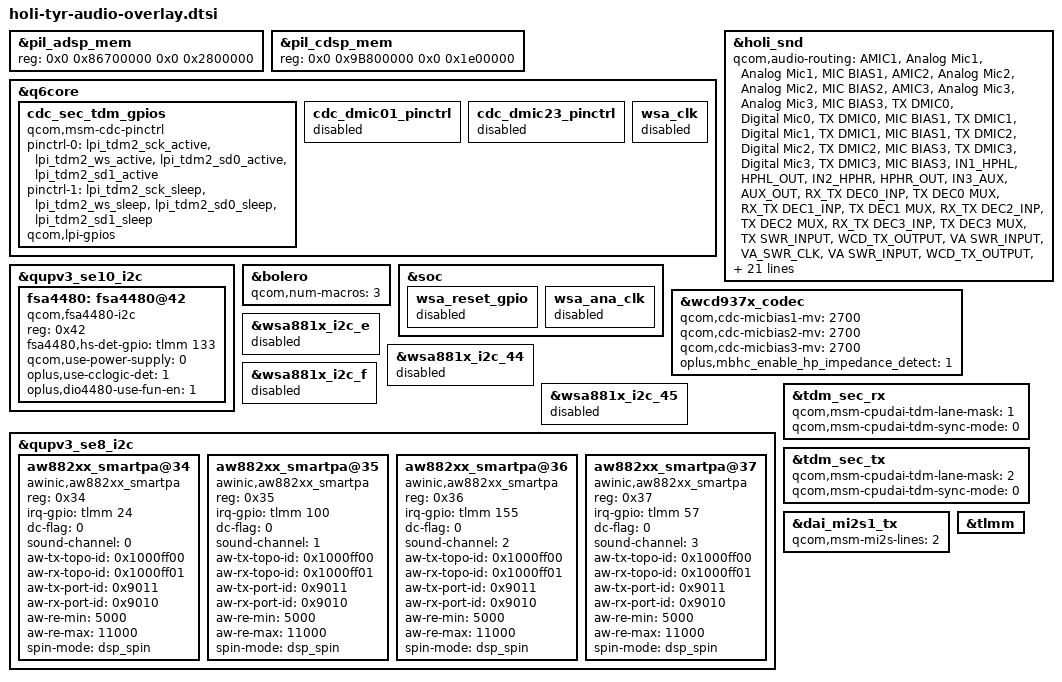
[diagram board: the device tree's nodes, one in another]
/**********************************************************************************
** File: - mozart-holi-audio-overlay.dtsi
**
** Copyright (C), 2021-2022, OPLUS Mobile Comm Corp., Ltd
**
** Description:
**     OPLUS Audio Module Device Tree.
**
** Version: 1.0
** --------------------------- Revision History: --------------------------------
**             <author>                      <date>                  <desc>
***********************************************************************************/
//#include "oplus-smartpa-sia81xx.dtsi"
&pil_adsp_mem {
	reg = <0x0 0x86700000 0x0 0x2800000>;
};

&pil_cdsp_mem {
	reg = <0x0 0x9B800000 0x0 0x1e00000>;
};

&q6core {
        cdc_sec_tdm_gpios: cdc_sec_tdm_gpios {
                compatible = "qcom,msm-cdc-pinctrl";
                pinctrl-names = "aud_active", "aud_sleep";
                pinctrl-0 = <&lpi_tdm2_sck_active &lpi_tdm2_ws_active
                             &lpi_tdm2_sd0_active &lpi_tdm2_sd1_active>;
                pinctrl-1 = <&lpi_tdm2_sck_sleep &lpi_tdm2_ws_sleep
                             &lpi_tdm2_sd0_sleep &lpi_tdm2_sd1_sleep>;
                qcom,lpi-gpios;
                #gpio-cells = <0>;
        };
        cdc_dmic01_pinctrl {
                status = "disabled";
        };

        cdc_dmic23_pinctrl {
                status = "disabled";
        };

        wsa_clk {
                status = "disabled";
        };
};

&holi_snd {
	qcom,audio-routing =
		"AMIC1", "Analog Mic1",
		"Analog Mic1", "MIC BIAS1",
		"AMIC2", "Analog Mic2",
		"Analog Mic2", "MIC BIAS2",
		"AMIC3", "Analog Mic3",
		"Analog Mic3", "MIC BIAS3",
		"TX DMIC0", "Digital Mic0",
		"TX DMIC0", "MIC BIAS1",
		"TX DMIC1", "Digital Mic1",
		"TX DMIC1", "MIC BIAS1",
		"TX DMIC2", "Digital Mic2",
		"TX DMIC2", "MIC BIAS3",
		"TX DMIC3", "Digital Mic3",
		"TX DMIC3", "MIC BIAS3",
		"IN1_HPHL", "HPHL_OUT",
		"IN2_HPHR", "HPHR_OUT",
		"IN3_AUX", "AUX_OUT",
		"RX_TX DEC0_INP", "TX DEC0 MUX",
		"RX_TX DEC1_INP", "TX DEC1 MUX",
		"RX_TX DEC2_INP", "TX DEC2 MUX",
		"RX_TX DEC3_INP", "TX DEC3 MUX",
		"TX SWR_INPUT", "WCD_TX_OUTPUT",
		"VA SWR_INPUT", "VA_SWR_CLK",
		"VA SWR_INPUT", "WCD_TX_OUTPUT",
		"VA_AIF1 CAP", "VA_SWR_CLK",
		"VA_AIF2 CAP", "VA_SWR_CLK",
		"VA_AIF3 CAP", "VA_SWR_CLK",
		"VA DMIC0", "Digital Mic0",
		"VA DMIC1", "Digital Mic1",
		"VA DMIC2", "Digital Mic2",
		"VA DMIC3", "Digital Mic3",
		"VA DMIC4", "Digital Mic4",
		"VA DMIC5", "Digital Mic5",
		"VA DMIC0", "VA MIC BIAS1",
		"VA DMIC1", "VA MIC BIAS1",
		"VA DMIC2", "VA MIC BIAS3",
		"VA DMIC3", "VA MIC BIAS3";
	qcom,msm-mbhc-moist-cfg = <1>, <3>, <0>;
	qcom,msm-mbhc-usbc-audio-supported = <1>;
	qcom,msm-mbhc-hphl-swh = <1>;
	qcom,msm-mbhc-gnd-swh = <1>;
	qcom,msm-mbhc-hs-mic-max-threshold-mv = <2600>;
	qcom,msm-mbhc-hs-mic-min-threshold-mv = <75>;

	qcom,sec-mi2s-gpios = <&cdc_sec_tdm_gpios>;

	oplus,mbhc-check-cross-conn = <0>;

	oplus,mbhc-headset-micbias-alwayon = <1>;

	qcom,mi2s-audio-intf = <1>;
	//qcom,auxpcm-audio-intf = <1>;
	//qcom,tdm-audio-intf = <1>;

	/delete-property/ qcom,cdc-dmic01-gpios;
	/delete-property/ qcom,cdc-dmic23-gpios;

	oplus,speaker-pa = "aw882xx";

	fsa4480-i2c-handle = <&fsa4480>;
};

&qupv3_se10_i2c {
        status = "okay";
        fsa4480: fsa4480@42 {
                compatible = "qcom,fsa4480-i2c";
                status = "okay";
                reg = <0x42>;
                fsa4480,hs-det-gpio = <&tlmm 133 0>;
                qcom,use-power-supply = <0>;
                oplus,use-cclogic-det = <1>;
                oplus,dio4480-use-fun-en = <1>;
        };
};

&bolero {
        qcom,num-macros = <3>;
};

&soc {
        /*oplus,audio-drv {
                compatible = "oplus,asoc-audio";
                //for nxp speaker
                oplus,speaker-vendor = "nxp";
                oplus,speaker-i2s-id = <0>;
                oplus,speaker-codec-name = "tfa98xx.2-0034";
                oplus,speaker-codec-dai-name = "tfa98xx-aif-2-34";
        };*/

        wsa_reset_gpio {
                status = "disabled";
        };

        wsa_ana_clk {
                status = "disabled";
        };
};

&wcd937x_codec {
	qcom,cdc-micbias1-mv = <2700>;
	qcom,cdc-micbias2-mv = <2700>;
	qcom,cdc-micbias3-mv = <2700>;
	oplus,mbhc_enable_hp_impedance_detect = <1>;
};

&wsa881x_i2c_e {
	status = "disabled";
};

&wsa881x_i2c_44 {
	status = "disabled";
};

&wsa881x_i2c_f {
	status = "disabled";
};

&wsa881x_i2c_45 {
	status = "disabled";
};

&qupv3_se8_i2c {
	status = "okay";
	aw882xx_smartpa@34 {
		compatible = "awinic,aw882xx_smartpa";
		reg = <0x34>;
		//reset-gpio = <&tlmm 84 0>;
		irq-gpio = <&tlmm 24 0x2008>;
		dc-flag = <0>;
		/*0:pri_l 1:pri_r 2:sec_l 3:sec_r*/
		sound-channel = <0>;
		aw-tx-topo-id = <0x1000ff00>;
		aw-rx-topo-id = <0x1000ff01>;
		aw-tx-port-id = <0x9011>;
		aw-rx-port-id = <0x9010>;
		aw-re-min = <5000>;
		aw-re-max= <11000>;
		spin-mode = "dsp_spin";
		/*aw-cali-mode = "none";*/
		status = "okay";
	};
	aw882xx_smartpa@35 {
		compatible = "awinic,aw882xx_smartpa";
		reg = <0x35>;
		//reset-gpio = <&tlmm 82 0>;
		irq-gpio = <&tlmm 100 0x2008>;
		dc-flag = <0>;
		/*0:pri_l 1:pri_r 2:sec_l 3:sec_r*/
		sound-channel = <1>;
		aw-tx-topo-id = <0x1000ff00>;
		aw-rx-topo-id = <0x1000ff01>;
		aw-tx-port-id = <0x9011>;
		aw-rx-port-id = <0x9010>;
		aw-re-min = <5000>;
		aw-re-max= <11000>;
		spin-mode = "dsp_spin";
		/*aw-cali-mode = "none";*/
		status = "okay";
	};
	aw882xx_smartpa@36 {
		compatible = "awinic,aw882xx_smartpa";
		reg = <0x36>;
		//reset-gpio = <&tlmm 82 0>;
		irq-gpio = <&tlmm 155 0x2008>;
		dc-flag = <0>;
		/*0:pri_l 1:pri_r 2:sec_l 3:sec_r*/
		sound-channel = <2>;
		aw-tx-topo-id = <0x1000ff00>;
		aw-rx-topo-id = <0x1000ff01>;
		aw-tx-port-id = <0x9011>;
		aw-rx-port-id = <0x9010>;
		aw-re-min = <5000>;
		aw-re-max= <11000>;
		spin-mode = "dsp_spin";
		/*aw-cali-mode = "none";*/
		status = "okay";
	};
	aw882xx_smartpa@37 {
		compatible = "awinic,aw882xx_smartpa";
		reg = <0x37>;
		//reset-gpio = <&tlmm 82 0>;
		irq-gpio = <&tlmm 57 0x2008>;
		dc-flag = <0>;
		/*0:pri_l 1:pri_r 2:sec_l 3:sec_r*/
		sound-channel = <3>;
		aw-tx-topo-id = <0x1000ff00>;
		aw-rx-topo-id = <0x1000ff01>;
		aw-tx-port-id = <0x9011>;
		aw-rx-port-id = <0x9010>;
		aw-re-min = <5000>;
		aw-re-max= <11000>;
		spin-mode = "dsp_spin";
		/*aw-cali-mode = "none";*/
		status = "okay";
	};

};

&tdm_sec_rx {
	qcom,msm-cpudai-tdm-lane-mask = /bits/ 16 <1>;
	qcom,msm-cpudai-tdm-sync-mode = <0>;
};

&tdm_sec_tx {
	qcom,msm-cpudai-tdm-lane-mask = /bits/ 16 <2>;
	qcom,msm-cpudai-tdm-sync-mode = <0>;
};

&dai_mi2s1_tx {
	qcom,msm-mi2s-lines = <2>;
};

&tlmm {
	/delete-node/  cam_sensor_rear_vana;
};

/*&smb1396 {
	status = "disabled";
};*/

/*
&qupv3_se10_i2c {
        status = "disabled";
        tfa98xx@34 {
                compatible = "nxp,tfa98xx";
                reg = <0x34>;
                tfa9874_vdd-supply = <&L9A>;
                tfa_min_range = <5000>;
                tfa_max_range = <7800>;
                reset-gpio = <&tlmm 11 0x00>;
                //tfa_channel = <1>;
                status = "okay";
        };
};
*/
/*
&dai_mi2s0 {
        compatible = "qcom,msm-dai-q6-mi2s";
        qcom,msm-dai-q6-mi2s-dev-id = <0>;
        qcom,msm-mi2s-rx-lines = <1>;
        qcom,msm-mi2s-tx-lines = <2>;
};
*/
